# SAMA7G54D1G device description
Architecture: CORTEX-A7; Family: SAMA; Series: SAMA7G
Registers are 32-bit, read-write, reset 0x0 unless marked. A register's access mark holds for its fields unless they carry their own. Offsets are from the block's base; [hi:lo] are bit positions.

## PIT64B — Periodic Interval Timer 64-bit
Instances: PIT64B0 0xE1800000, PIT64B1 0xE1804000, PIT64B2 0xE1808000, PIT64B3 0xE2004000, PIT64B4 0xE2008000, PIT64B5 0xE2810000
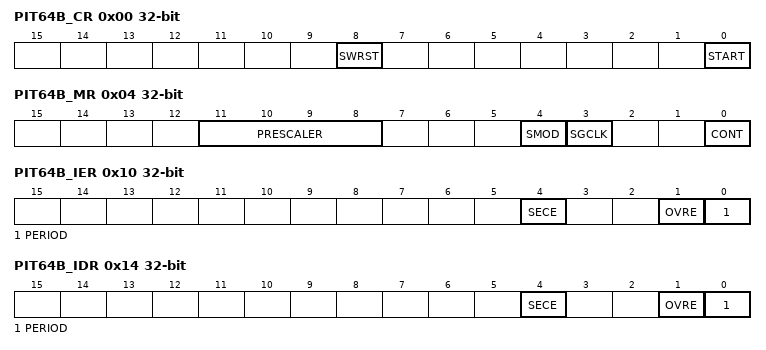
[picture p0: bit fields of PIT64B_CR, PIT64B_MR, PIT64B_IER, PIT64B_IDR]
0x00 PIT64B_CR wo reset not defined — Control Register
  [8] SWRST — Software Reset
    0=No effect; 1=Performs a software reset, clears the configuration and stops any timer period in progress
  [0] START — Start Timer
    0=No effect; 1=The timer counter is started for 1 or more periods. If the START command is applied during a non-elapsed timer period, there is no effect. Thus, in Continuous mode, the SWRST command is the only command to stop the PIT64B.
0x04 PIT64B_MR — Mode Register
  [11:8] PRESCALER — Prescaler Period
    0=A prescaler divider of 1 is used
  [4] SMOD — Start Mode
    0=Writing PIT64B_LSBPR does not start the timer period; 1=Writing PIT64B_LSBPR starts the timer period
  [3] SGCLK — Generic Clock Selection Enable
    0=The prescaler is triggered at each rising edge of "Peripheral clock" and the timer is triggered; 1=GCLK clock is selected as clock source of the 8-bit prescaler
  [0] CONT — Continuous Mode
    0=A single period interrupt is generated from a START command; 1=Continuous periodic interrupts are generated after a single START command
0x08 PIT64B_LSBPR — LSB Period Register
  [31:0] LSBPERIOD — 32 LSB of the Timer Period
0x0C PIT64B_MSBPR — MSB Period Register
  [31:0] MSBPERIOD — 32 MSB of the Timer Period
0x10 PIT64B_IER wo reset not defined (atomic set of PIT64B_IMR) — Interrupt Enable Register
  [4] SECE — Safety and/or Security Report Interrupt Enable
  [1] OVRE — Overrun Error Interrupt Enable
  [0] PERIOD — Elapsed Timer Period Interrupt Enable
0x14 PIT64B_IDR wo reset not defined (atomic clear of PIT64B_IMR) — Interrupt Disable Register
  [4] SECE — Safety and/or Security Report Interrupt Disable
  [1] OVRE — Overrun Error Interrupt Disable
  [0] PERIOD — Elapsed Timer Period Interrupt Disable
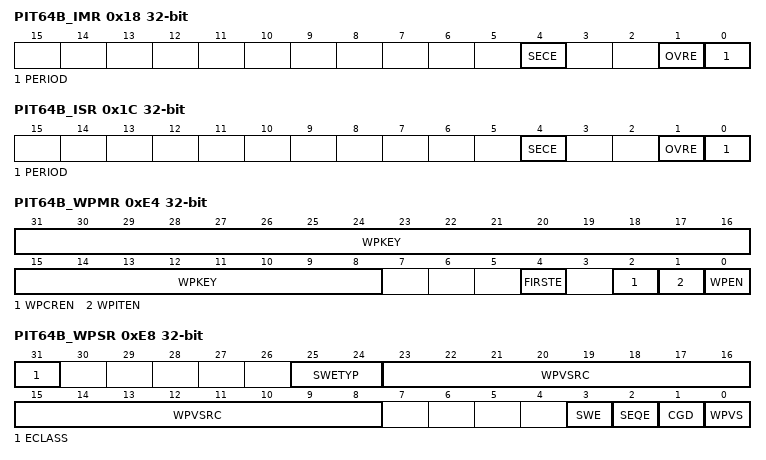
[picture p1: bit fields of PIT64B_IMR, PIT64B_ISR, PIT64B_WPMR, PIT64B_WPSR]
0x18 PIT64B_IMR ro — Interrupt Mask Register
  [4] SECE — Safety and/or Security Report Interrupt Mask
  [1] OVRE — Overrun Error Interrupt Mask
  [0] PERIOD — Elapsed Timer Period Interrupt Mask
0x1C PIT64B_ISR ro — Interrupt Status Register
  [4] SECE — Safety/Security Report (cleared on read)
    0=There is no security report in PIT64B_WPSR since the last read of PIT64B_ISR; 1=One security flag is set in PIT64B_WPSR since the last read of PIT64B_ISR
  [1] OVRE — Overrun Error (cleared on read)
    0=No multiple rollovers occurred since the last read of PIT64B_ISR; 1=More than 1 rollover occurred since the last read of PIT64B_ISR
  [0] PERIOD — Elapsed Timer Period Status Flag (cleared on read)
    0=No timer rollover occurred since the last read of PIT64B_ISR; 1=A timer rollover occurred since the last read of PIT64B_ISR
0x20 PIT64B_TLSBR ro — Timer LSB Current Value Register
  [31:0] LSBTIMER — Current 32 LSB of the Timer
0x24 PIT64B_TMSBR ro — Timer MSB Current Value Register
  [31:0] MSBTIMER — Current 32 MSB of the Timer
0xE4 PIT64B_WPMR — Write Protection Mode Register
  [31:8] WPKEY — Write Protection Key
    0x504954=PASSWD (Writing any other value in this field aborts the write operation of the WPCREN, WPITEN and WPEN bits. Always reads as 0.)
  [4] FIRSTE — First Error Report Enable
    0=The last write protection violation source is reported in PIT64B_WPSR.WPVSRC and the last software control error type is reported in PIT64B_WPSR.SWETYP. The PIT64B_ISR.SECE flag is set at the first error occurring within a series.; 1=Only the first write protection violation source is reported in PIT64B_WPSR.WPVSRC and only the first software control error type is reported in PIT64B_WPSR.SWETYP. The PIT64B_ISR.SECE flag is set at the first error occurring within a series.
  [2] WPCREN — Write Protection Control Enable
    0=Disables the write protection on control register if WPKEY corresponds to 0x504954 ("PIT" in ASCII); 1=Enables the write protection on control register if WPKEY corresponds to 0x504954 ("PIT" in ASCII)
  [1] WPITEN — Write Protection Interruption Enable
    0=Disables the write protection on interrupt registers if WPKEY corresponds to 0x504954 ("PIT" in ASCII); 1=Enables the write protection on interrupt registers if WPKEY corresponds to 0x504954 ("PIT" in ASCII)
  [0] WPEN — Write Protection Enable
    0=Disables the write protection if WPKEY corresponds to 0x504954 ("PIT" in ASCII); 1=Enables the write protection if WPKEY corresponds to 0x504954 ("PIT" in ASCII)
0xE8 PIT64B_WPSR ro — Write Protection Status Register
  [31] ECLASS — Software Error Class (cleared on read)
    0=WARNING (An abnormal access that does not affect system functionality.); 1=ERROR (A write access is performed into PIT64B_MR, PIT64B_LSBR, PIT64B_MSBR while the PIT64B is running.)
  [25:24] SWETYP — Software Error Type (cleared on read)
    0=READ_WO (A write-only register has been read (warning).); 1=WRITE_RO (A write access has been performed on a read-only register (Warning).); 2=UNDEF_RW (Access to an undefined address (warning).); 3=WEIRD_ACTION (A write access is performed into PIT64B_MR, PIT64B_LSBR, PIT64B_MSBR while the PIT64B is running (abnormal).)
  [23:8] WPVSRC — Write Protection Violation Source
  [3] SWE — Software Control Error (cleared on read)
    0=No software error has occurred since the last read of PIT64B_WPSR; 1=A software error has occurred since the last read of PIT64B_WPSR. The field SWETYP details the type of software error; the associated incorrect software access is reported in the field WPVSRC (if WPVS=0).
  [2] SEQE — Internal Sequencer Error (cleared on read)
    0=No peripheral internal sequencer error has occurred since the last read of PIT64B_WPSR; 1=A peripheral internal sequencer error has occurred since the last read of PIT64B_WPSR. This flag can only be set under abnormal operating conditions.
  [1] CGD — Clock Glitch Detected (cleared on read)
    0=The clock monitoring circuitry has not been corrupted since the last read of PIT64B_WPSR. Under normal operating conditions, this bit is always cleared.; 1=The clock monitoring circuitry has been corrupted since the last read of PIT64B_WPSR. This flag can only be set in case of abnormal clock signal waveform (glitch).
  [0] WPVS — Write Protection Violation Status (cleared on read)
    0=No write protection violation has occurred since the last read of the PIT64B_WPSR; 1=A write protection violation has occurred since the last read of the PIT64B_WPSR. If this violation is an unauthorized attempt to write a protected register, the associated violation is reported into field WPVSRC.
